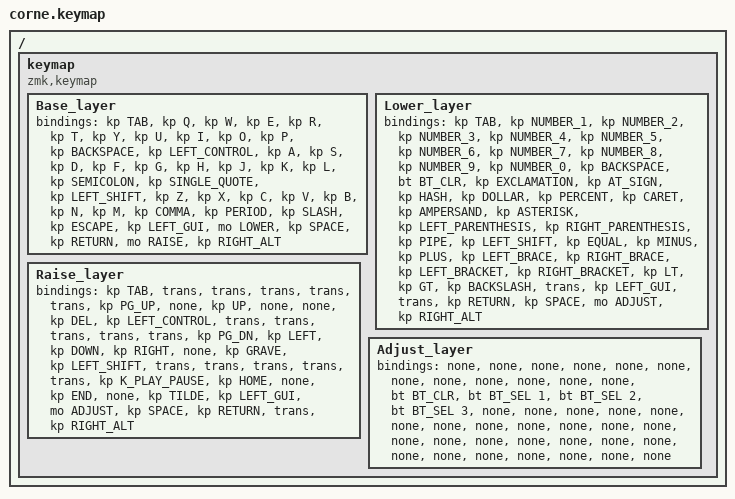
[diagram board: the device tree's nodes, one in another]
#include <behaviors.dtsi>
#include <dt-bindings/zmk/keys.h>
#include <dt-bindings/zmk/bt.h>

#define BASE 0
#define LOWER 1
#define RAISE 2
#define ADJUST 3

/ {
  keymap {
    compatible = "zmk,keymap";

    Base_layer {
      bindings = <
        &kp TAB &kp Q &kp W &kp E &kp R &kp T &kp Y &kp U &kp I &kp O &kp P &kp BACKSPACE &kp LEFT_CONTROL &kp A &kp S &kp D &kp F &kp G &kp H &kp J &kp K &kp L &kp SEMICOLON &kp SINGLE_QUOTE &kp LEFT_SHIFT &kp Z &kp X &kp C &kp V &kp B &kp N &kp M &kp COMMA &kp PERIOD &kp SLASH &kp ESCAPE &kp LEFT_GUI &mo LOWER &kp SPACE &kp RETURN &mo RAISE &kp RIGHT_ALT 
      >;
    };

    Lower_layer {
      bindings = <
        &kp TAB &kp NUMBER_1 &kp NUMBER_2 &kp NUMBER_3 &kp NUMBER_4 &kp NUMBER_5 &kp NUMBER_6 &kp NUMBER_7 &kp NUMBER_8 &kp NUMBER_9 &kp NUMBER_0 &kp BACKSPACE &bt BT_CLR &kp EXCLAMATION &kp AT_SIGN &kp HASH &kp DOLLAR &kp PERCENT &kp CARET &kp AMPERSAND &kp ASTERISK &kp LEFT_PARENTHESIS &kp RIGHT_PARENTHESIS &kp PIPE &kp LEFT_SHIFT &kp EQUAL &kp MINUS &kp PLUS &kp LEFT_BRACE &kp RIGHT_BRACE &kp LEFT_BRACKET &kp RIGHT_BRACKET &kp LT &kp GT &kp BACKSLASH &trans &kp LEFT_GUI &trans &kp RETURN &kp SPACE &mo ADJUST &kp RIGHT_ALT 
      >;
    };

    Raise_layer {
      bindings = <
        &kp TAB &trans &trans &trans &trans &trans &kp PG_UP &none &kp UP &none &none &kp DEL &kp LEFT_CONTROL &trans &trans &trans &trans &trans &kp PG_DN &kp LEFT &kp DOWN &kp RIGHT &none &kp GRAVE &kp LEFT_SHIFT &trans &trans &trans &trans &trans &kp K_PLAY_PAUSE &kp HOME &none &kp END &none &kp TILDE &kp LEFT_GUI &mo ADJUST &kp SPACE &kp RETURN &trans &kp RIGHT_ALT 
      >;
    };

    Adjust_layer {
      bindings = <
        &none &none &none &none &none &none &none &none &none &none &none &none &bt BT_CLR &bt BT_SEL 1 &bt BT_SEL 2 &bt BT_SEL 3 &none &none &none &none &none &none &none &none &none &none &none &none &none &none &none &none &none &none &none &none &none &none &none &none &none &none 
      >;
    };

  };
};
